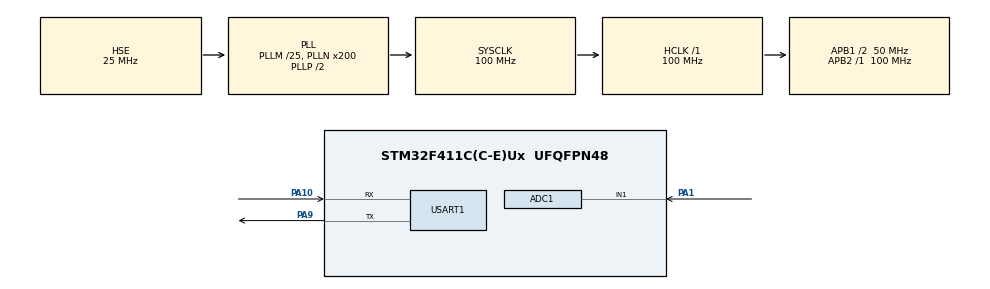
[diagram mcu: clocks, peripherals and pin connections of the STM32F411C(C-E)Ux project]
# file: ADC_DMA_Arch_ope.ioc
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ADC1.Channel-0\#ChannelRegularConversion=ADC_CHANNEL_1
ADC1.ContinuousConvMode=ENABLE
ADC1.NbrOfConversionFlag=1
ADC1.Rank-0\#ChannelRegularConversion=1
ADC1.SamplingTime-0\#ChannelRegularConversion=ADC_SAMPLETIME_3CYCLES
ADC1.master=1
Dma.ADC1.0.Direction=DMA_PERIPH_TO_MEMORY
Dma.ADC1.0.FIFOMode=DMA_FIFOMODE_DISABLE
Dma.ADC1.0.Instance=DMA2_Stream0
Dma.ADC1.0.MemDataAlignment=DMA_MDATAALIGN_WORD
Dma.ADC1.0.MemInc=DMA_MINC_ENABLE
Dma.ADC1.0.Mode=DMA_NORMAL
Dma.ADC1.0.PeriphDataAlignment=DMA_PDATAALIGN_WORD
Dma.ADC1.0.PeriphInc=DMA_PINC_DISABLE
Dma.ADC1.0.Priority=DMA_PRIORITY_LOW
Dma.Request0=ADC1
FREERTOS.Tasks01=defaultTask,24,128,StartDefaultTask,Default,NULL,Dynamic,NULL,NULL
Mcu.Family=STM32F4
Mcu.Name=STM32F411C(C-E)Ux
Mcu.Package=UFQFPN48
NVIC.DMA2_Stream0_IRQn=true\:5\:0\:false\:false\:true\:true\:false\:true\:true
NVIC.PriorityGroup=NVIC_PRIORITYGROUP_4
NVIC.TIM1_TRG_COM_TIM11_IRQn=true\:15\:0\:false\:false\:true\:false\:false\:true\:true
NVIC.TimeBase=TIM1_TRG_COM_TIM11_IRQn
NVIC.TimeBaseIP=TIM11
PA1.Signal=ADCx_IN1
PA10.Mode=Asynchronous
PA10.Signal=USART1_RX
PA13.Mode=Serial_Wire
PA13.Signal=SYS_JTMS-SWDIO
PA14.Mode=Serial_Wire
PA14.Signal=SYS_JTCK-SWCLK
PA9.Mode=Asynchronous
PA9.Signal=USART1_TX
PC14-OSC32_IN.Mode=LSE-External-Oscillator
PC14-OSC32_IN.Signal=RCC_OSC32_IN
PC15-OSC32_OUT.Mode=LSE-External-Oscillator
PC15-OSC32_OUT.Signal=RCC_OSC32_OUT
PH0\ -\ OSC_IN.Mode=HSE-External-Oscillator
PH0\ -\ OSC_IN.Signal=RCC_OSC_IN
PH1\ -\ OSC_OUT.Mode=HSE-External-Oscillator
PH1\ -\ OSC_OUT.Signal=RCC_OSC_OUT
ProjectManager.HeapSize=0x200
ProjectManager.StackSize=0x400
ProjectManager.TargetToolchain=MDK-ARM V5.32
RCC.48MHZClocksFreq_Value=50000000
RCC.AHBFreq_Value=100000000
RCC.APB1CLKDivider=RCC_HCLK_DIV2
RCC.APB1Freq_Value=50000000
RCC.APB1TimFreq_Value=100000000
RCC.APB2Freq_Value=100000000
RCC.APB2TimFreq_Value=100000000
RCC.CortexFreq_Value=100000000
RCC.HCLKFreq_Value=100000000
RCC.HSE_VALUE=25000000
RCC.HSI_VALUE=16000000
RCC.PLLM=25
RCC.PLLN=200
RCC.PLLSourceVirtual=RCC_PLLSOURCE_HSE
RCC.SYSCLKFreq_VALUE=100000000
RCC.SYSCLKSource=RCC_SYSCLKSOURCE_PLLCLK
RCC.VCOOutputFreq_Value=200000000
SH.ADCx_IN1.0=ADC1_IN1,IN1
USART1.VirtualMode=VM_ASYNC
VP_FREERTOS_VS_CMSIS_V2.Mode=CMSIS_V2
VP_SYS_VS_tim11.Mode=TIM11
board=custom

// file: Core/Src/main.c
/* USER CODE BEGIN Header */
/**
  ******************************************************************************
  * @file           : main.c
  * @brief          : Main program body
  ******************************************************************************
  * @attention
  *
  * Copyright (c) 2026 STMicroelectronics.
  * All rights reserved.
  *
  * This software is licensed under terms that can be found in the LICENSE file
  * in the root directory of this software component.
  * If no LICENSE file comes with this software, it is provided AS-IS.
  *
  ******************************************************************************
  */
/* USER CODE END Header */
#include "main.h"
#include "cmsis_os.h"
#include "adc.h"
#include "dma.h"
#include "usart.h"
#include "gpio.h"

/* USER CODE BEGIN Includes */
#include "SEGGER_RTT.h"
#include "elog.h"
#include "bsp_adc.h"
/* USER CODE END Includes */

void SystemClock_Config(void);
void MX_FREERTOS_Init(void);

int main(void)
{

  /* MCU Configuration--------------------------------------------------------*/

  /* Reset of all peripherals, Initializes the Flash interface and the Systick. */
  HAL_Init();

  /* Configure the system clock */
  SystemClock_Config();

  /* USER CODE BEGIN SysInit */
  SEGGER_RTT_Init();
  /* USER CODE END SysInit */

  /* Initialize all configured peripherals */
  MX_GPIO_Init();
  MX_DMA_Init();
  MX_ADC1_Init();
  MX_USART1_UART_Init();

  /* Init scheduler */
  osKernelInitialize();  /* Call init function for freertos objects (in freertos.c) */
  MX_FREERTOS_Init();

  /* Start scheduler */
  osKernelStart();
  /* We should never get here as control is now taken by the scheduler */
  /* Infinite loop */
  while (1)
  {

  }
}

void SystemClock_Config(void)
{
  RCC_OscInitTypeDef RCC_OscInitStruct = {0};
  RCC_ClkInitTypeDef RCC_ClkInitStruct = {0};

  /** Configure the main internal regulator output voltage
  */
  __HAL_RCC_PWR_CLK_ENABLE();
  __HAL_PWR_VOLTAGESCALING_CONFIG(PWR_REGULATOR_VOLTAGE_SCALE1);

  /** Initializes the RCC Oscillators according to the specified parameters
  * in the RCC_OscInitTypeDef structure.
  */
  RCC_OscInitStruct.OscillatorType = RCC_OSCILLATORTYPE_HSE;
  RCC_OscInitStruct.HSEState = RCC_HSE_ON;
  RCC_OscInitStruct.PLL.PLLState = RCC_PLL_ON;
  RCC_OscInitStruct.PLL.PLLSource = RCC_PLLSOURCE_HSE;
  RCC_OscInitStruct.PLL.PLLM = 25;
  RCC_OscInitStruct.PLL.PLLN = 200;
  RCC_OscInitStruct.PLL.PLLP = RCC_PLLP_DIV2;
  RCC_OscInitStruct.PLL.PLLQ = 4;
  if (HAL_RCC_OscConfig(&RCC_OscInitStruct) != HAL_OK)
  {
    Error_Handler();
  }

  /** Initializes the CPU, AHB and APB buses clocks
  */
  RCC_ClkInitStruct.ClockType = RCC_CLOCKTYPE_HCLK|RCC_CLOCKTYPE_SYSCLK
                              |RCC_CLOCKTYPE_PCLK1|RCC_CLOCKTYPE_PCLK2;
  RCC_ClkInitStruct.SYSCLKSource = RCC_SYSCLKSOURCE_PLLCLK;
  RCC_ClkInitStruct.AHBCLKDivider = RCC_SYSCLK_DIV1;
  RCC_ClkInitStruct.APB1CLKDivider = RCC_HCLK_DIV2;
  RCC_ClkInitStruct.APB2CLKDivider = RCC_HCLK_DIV1;

  if (HAL_RCC_ClockConfig(&RCC_ClkInitStruct, FLASH_LATENCY_3) != HAL_OK)
  {
    Error_Handler();
  }
}

void HAL_TIM_PeriodElapsedCallback(TIM_HandleTypeDef *htim)
{
  if (htim->Instance == TIM11) {
    HAL_IncTick();
  }
}

void Error_Handler(void)
{
  __disable_irq();
  while (1)
  {
  }
}

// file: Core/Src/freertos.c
/* USER CODE BEGIN Header */
/**
  ******************************************************************************
  * File Name          : freertos.c
  * Description        : Code for freertos applications
  ******************************************************************************
  * @attention
  *
  * Copyright (c) 2026 STMicroelectronics.
  * All rights reserved.
  *
  * This software is licensed under terms that can be found in the LICENSE file
  * in the root directory of this software component.
  * If no LICENSE file comes with this software, it is provided AS-IS.
  *
  ******************************************************************************
  */
/* USER CODE END Header */

#include "FreeRTOS.h"
#include "task.h"
#include "main.h"
#include "cmsis_os.h"

/* USER CODE BEGIN Includes */
#include "elog.h"
#include "bsp_adc.h"
/* USER CODE END Includes */

/* USER CODE BEGIN PD */
//#define LOG_TAG "FREERTOS"
/* USER CODE END PD */

/* Definitions for defaultTask */
osThreadId_t defaultTaskHandle;
const osThreadAttr_t defaultTask_attributes = {
  .name = "defaultTask",
  .stack_size = 128 * 4,
  .priority = (osPriority_t) osPriorityNormal,
};

/* USER CODE BEGIN FunctionPrototypes */
void app_elog_init(void);
/* USER CODE END FunctionPrototypes */

void StartDefaultTask(void *argument);

void MX_FREERTOS_Init(void); /* (MISRA C 2004 rule 8.1) */

void MX_FREERTOS_Init(void) {

  /* Create the thread(s) */
  /* creation of defaultTask */
  defaultTaskHandle = osThreadNew(StartDefaultTask, NULL, &defaultTask_attributes);

  /* USER CODE BEGIN RTOS_THREADS */
  /* add threads, ... */
	BSP_ADC_Init();

  /* USER CODE END RTOS_THREADS */

  /* USER CODE BEGIN RTOS_EVENTS */
  /* add events, ... */
	app_elog_init();
  /* USER CODE END RTOS_EVENTS */

}

void StartDefaultTask(void *argument)
{
  /* USER CODE BEGIN StartDefaultTask */
  /* Infinite loop */
  for(;;)
  {
    //log_i("HELLO");
    osDelay(10000);
  }
  /* USER CODE END StartDefaultTask */
}

/* USER CODE BEGIN Application */
/**
 * @brief Initialize the easylogger module.
 * @param None
 * @retval None
 */
void app_elog_init(void){
  elog_init();
  /* Set the log format */
  elog_set_fmt(ELOG_LVL_ASSERT, ELOG_FMT_ALL);
  elog_set_fmt(ELOG_LVL_ERROR, ELOG_FMT_ALL);
  elog_set_fmt(ELOG_LVL_WARN, ELOG_FMT_ALL);
  elog_set_fmt(ELOG_LVL_INFO, ELOG_FMT_ALL);
  elog_set_fmt(ELOG_LVL_DEBUG, ELOG_FMT_ALL);
  /* Set the output interface */
  elog_set_filter_lvl(ELOG_LVL_VERBOSE);
  elog_start();
}
/* USER CODE END Application */
